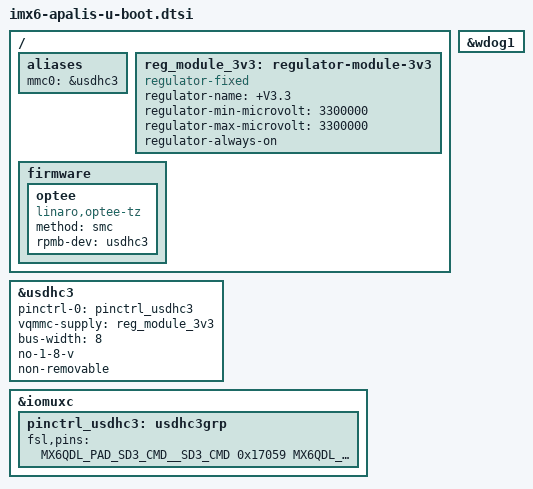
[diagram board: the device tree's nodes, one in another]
// SPDX-License-Identifier: GPL-2.0+ OR X11
/*
 * Copyright 2020 Foundries.IO
 */

#include "imx6qdl-u-boot.dtsi"

/ {

	aliases {
		mmc0 = &usdhc3;
	};

	reg_module_3v3: regulator-module-3v3 {
		compatible = "regulator-fixed";
		regulator-name = "+V3.3";
		regulator-min-microvolt = <3300000>;
		regulator-max-microvolt = <3300000>;
		regulator-always-on;
	};

	firmware {
		optee {
			compatible = "linaro,optee-tz";
			method = "smc";
			rpmb-dev = <&usdhc3>;
		};
	};
};

&wdog1 {
	status = "okay";
	u-boot,dm-spl;
};

/* eMMC */
&usdhc3 {
	pinctrl-names = "default";
	pinctrl-0 = <&pinctrl_usdhc3>;
	vqmmc-supply = <&reg_module_3v3>;
	bus-width = <8>;
	no-1-8-v;
	non-removable;
	status = "okay";
};


&iomuxc {
	pinctrl_usdhc3: usdhc3grp {
		fsl,pins = <
			MX6QDL_PAD_SD3_CMD__SD3_CMD	0x17059
			MX6QDL_PAD_SD3_CLK__SD3_CLK	0x10059
			MX6QDL_PAD_SD3_DAT0__SD3_DATA0	0x17059
			MX6QDL_PAD_SD3_DAT1__SD3_DATA1	0x17059
			MX6QDL_PAD_SD3_DAT2__SD3_DATA2	0x17059
			MX6QDL_PAD_SD3_DAT3__SD3_DATA3	0x17059
			MX6QDL_PAD_SD3_DAT4__SD3_DATA4	0x17059
			MX6QDL_PAD_SD3_DAT5__SD3_DATA5	0x17059
			MX6QDL_PAD_SD3_DAT6__SD3_DATA6	0x17059
			MX6QDL_PAD_SD3_DAT7__SD3_DATA7	0x17059
			/* eMMC reset */
			MX6QDL_PAD_SD3_RST__SD3_RESET	0x17059
		>;
	};
};
